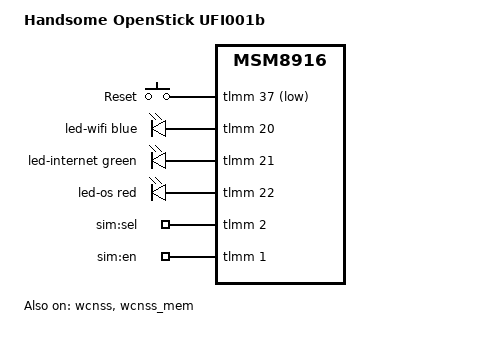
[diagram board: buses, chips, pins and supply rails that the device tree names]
// SPDX-License-Identifier: GPL-2.0-only
/*
 * Handsome OpenStick UFI001b - MSM8916 4G USB stick
 *
 * Board layout (based on HandsomeMod 5.10 DTS):
 *   - Wi-Fi/BT: WCN3660b (pronto v2)
 *   - Reset button: GPIO 37
 *   - LEDs: wifi=20, internet=21, os=22,
 *     sim_sel=2 (default on), sim_en=1  (single SIM, no sel2/en2)
 *   - eMMC: sdhc_1
 */

/dts-v1/;

#include "msm8916-handsome-openstick-common.dtsi"
#include <dt-bindings/leds/common.h>

/ {
	model = "Handsome OpenStick UFI001b";
	compatible = "handsome,openstick", "qcom,msm8916";

	gpio-keys {
		compatible = "gpio-keys";

		pinctrl-names = "default";
		pinctrl-0 = <&gpio_keys_default>;

		button-reset {
			label = "Reset";
			gpios = <&tlmm 37 GPIO_ACTIVE_LOW>;
			linux,code = <KEY_RESTART>;
		};
	};

	leds {
		compatible = "gpio-leds";

		pinctrl-names = "default";
		pinctrl-0 = <&gpio_leds_default>;

		led-wifi {
			function = LED_FUNCTION_WLAN;
			color = <LED_COLOR_ID_BLUE>;
			gpios = <&tlmm 20 GPIO_ACTIVE_HIGH>;
			linux,default-trigger = "phy0tx";
		};

		led-internet {
			function = LED_FUNCTION_WAN;
			color = <LED_COLOR_ID_GREEN>;
			gpios = <&tlmm 21 GPIO_ACTIVE_HIGH>;
		};

		led-os {
			function = LED_FUNCTION_HEARTBEAT;
			color = <LED_COLOR_ID_RED>;
			gpios = <&tlmm 22 GPIO_ACTIVE_HIGH>;
			linux,default-trigger = "heartbeat";
			default-state = "on";
		};

		led-sim-sel {
			label = "sim:sel";
			gpios = <&tlmm 2 GPIO_ACTIVE_HIGH>;
			default-state = "on";
		};

		led-sim-en {
			label = "sim:en";
			gpios = <&tlmm 1 GPIO_ACTIVE_HIGH>;
		};
	};
};

&wcnss {
	status = "okay";
};

&wcnss_iris {
	compatible = "qcom,wcn3660b";
};

&wcnss_mem {
	status = "okay";
};

/*
 * CPU overclocking (SAW2 auto-scales via pm8916_s3).
 * UFI001b handles up to 1.6GHz stably.
 */
&cpu_opp_table {
	opp-1000000000 {
		opp-hz = /bits/ 64 <1000000000>;
	};
	opp-1100000000 {
		opp-hz = /bits/ 64 <1100000000>;
	};
	opp-1200000000 {
		opp-hz = /bits/ 64 <1200000000>;
	};
	opp-1300000000 {
		opp-hz = /bits/ 64 <1300000000>;
	};
	opp-1400000000 {
		opp-hz = /bits/ 64 <1400000000>;
	};
	opp-1500000000 {
		opp-hz = /bits/ 64 <1500000000>;
	};
	opp-1600000000 {
		opp-hz = /bits/ 64 <1600000000>;
	};
};

&tlmm {
	gpio_leds_default: gpio-leds-default-state {
		pins = "gpio1", "gpio2",
		       "gpio20", "gpio21", "gpio22";
		function = "gpio";
		bias-disable;
	};

	gpio_keys_default: gpio-keys-default-state {
		pins = "gpio37";
		function = "gpio";

		drive-strength = <8>;
		input-enable;
		bias-pull-up;
	};
};
